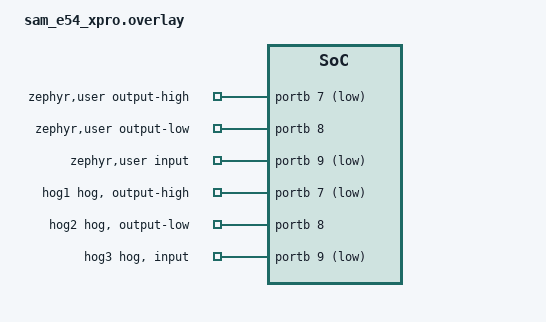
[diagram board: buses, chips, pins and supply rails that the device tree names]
/*
 * Copyright (c) 2026 Microchip Technology Inc.
 *
 * SPDX-License-Identifier: Apache-2.0
 */

#include <zephyr/dt-bindings/gpio/gpio.h>

/ {
	zephyr,user {
		output-high-gpios = <&portb 7 GPIO_ACTIVE_LOW>;
		output-low-gpios = <&portb 8 GPIO_ACTIVE_HIGH>;
		input-gpios = <&portb 9 GPIO_ACTIVE_LOW>;
	};
};

&portb {
	status = "okay";

	hog1 {
		gpio-hog;
		gpios = <7 GPIO_ACTIVE_LOW>;
		output-high;
	};

	hog2 {
		gpio-hog;
		gpios = <8 GPIO_ACTIVE_HIGH>;
		output-low;
	};

	hog3 {
		gpio-hog;
		gpios = <9 GPIO_ACTIVE_LOW>;
		input;
	};
};
